# M3H6 register map
File version: 0.1
Registers are 32-bit, read-write, reset 0x0 unless marked. A register's access mark holds for its fields unless they carry their own. Offsets are from the block's base; [hi:lo] are bit positions; {n}, {i} and the like mark numbered series.

## PB — Port B
Base 0x400C0100
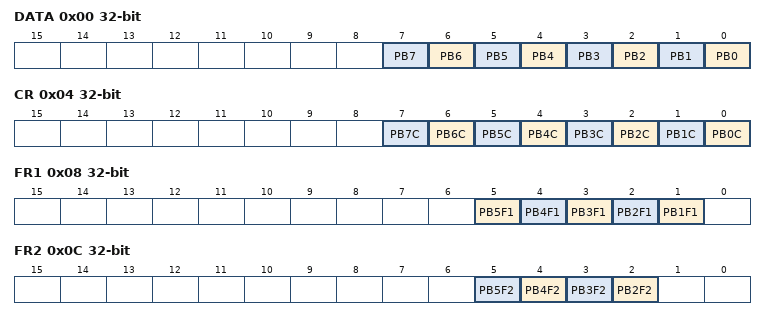
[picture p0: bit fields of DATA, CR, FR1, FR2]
0x00 DATA — PB Data Register
  [n] PB{n} (n=0..7)
0x04 CR — PB Control Register
  [n] PB{n}C (n=0..7)
0x08 FR1 — PB Function Register 1
  [n] PB{n}F1 (n=1..5)
0x0C FR2 — PB Function Register 2
  [n] PB{n}F2 (n=2..5)
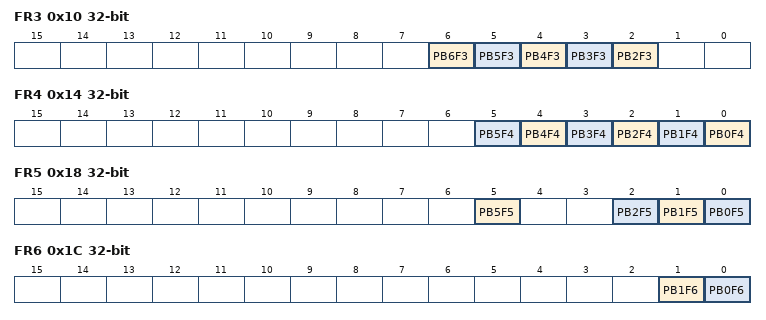
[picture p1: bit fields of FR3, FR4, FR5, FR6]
0x10 FR3 — PB Function Register 3
  [n] PB{n}F3 (n=2..6)
0x14 FR4 — PB Function Register 4
  [n] PB{n}F4 (n=0..5)
0x18 FR5 — PB Function Register 5
  [5] PB5F5, [2] PB2F5, [1] PB1F5, [0] PB0F5
0x1C FR6 — PB Function Register 6
  [1] PB1F6, [0] PB0F6
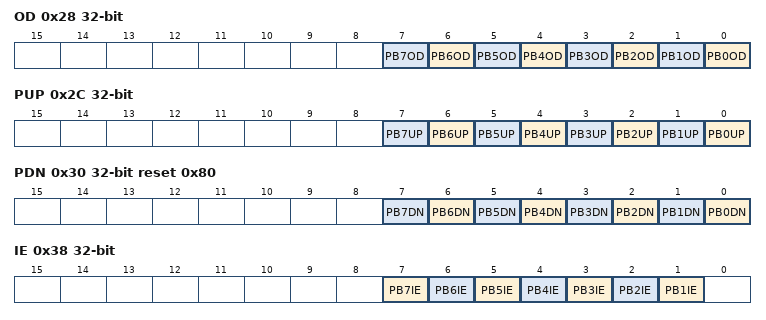
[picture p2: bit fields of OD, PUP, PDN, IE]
0x28 OD — PB Open Drain Control Register
  [n] PB{n}OD (n=0..7)
0x2C PUP — PB Pull-up Control Register
  [n] PB{n}UP (n=0..7)
0x30 PDN reset 0x80 — PB Pull-Down Control Register
  [n] PB{n}DN (n=0..7)
0x38 IE — PB Input Enable Control Register
  [n] PB{n}IE (n=1..7)

## PC — Port C
Base 0x400C0200
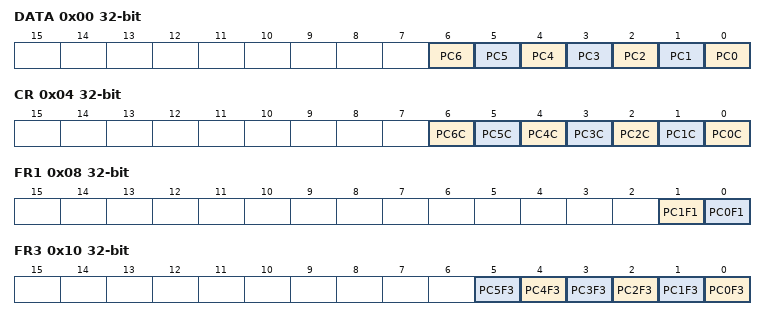
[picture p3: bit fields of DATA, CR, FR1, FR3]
0x00 DATA — PC Data Register
  [n] PC{n} (n=0..6)
0x04 CR — PC Control Register
  [n] PC{n}C (n=0..6)
0x08 FR1 — PC Function Register 1
  [1] PC1F1, [0] PC0F1
0x10 FR3 — PC Function Register 3
  [n] PC{n}F3 (n=0..5)
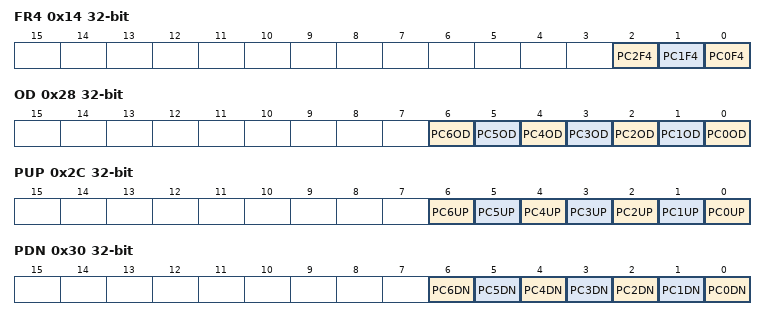
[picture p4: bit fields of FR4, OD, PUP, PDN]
0x14 FR4 — PC Function Register 4
  [2] PC2F4, [1] PC1F4, [0] PC0F4
0x18 FR5 — PC Function Register 5
  [2] PC2F5
0x28 OD — PC Open Drain Control Register
  [n] PC{n}OD (n=0..6)
0x2C PUP — PC Pull-up Control Register
  [n] PC{n}UP (n=0..6)
0x30 PDN — PC Pull-Down Control Register
  [n] PC{n}DN (n=0..6)
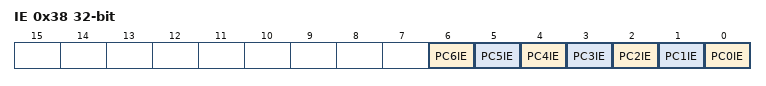
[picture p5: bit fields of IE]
0x38 IE — PC Input Enable Control Register
  [n] PC{n}IE (n=0..6)

## PD — Port D
Base 0x400C0300
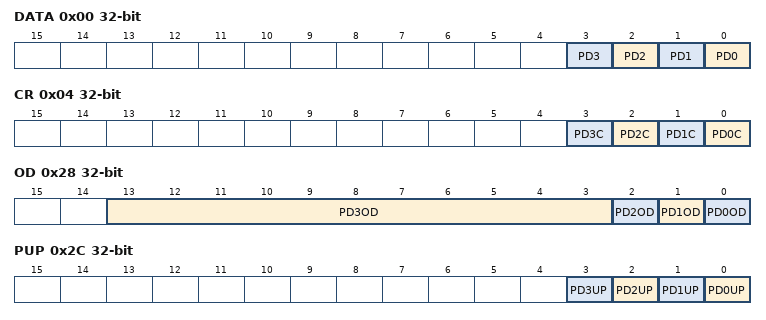
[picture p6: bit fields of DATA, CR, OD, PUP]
0x00 DATA — PD Data Register
  [n] PD{n} (n=0..3)
0x04 CR — PD Control Register
  [n] PD{n}C (n=0..3)
0x28 OD — PD Open Drain Control Register
  [13:3] PD3OD, [2] PD2OD, [1] PD1OD, [0] PD0OD
0x2C PUP — PD Pull-up Control Register
  [n] PD{n}UP (n=0..3)
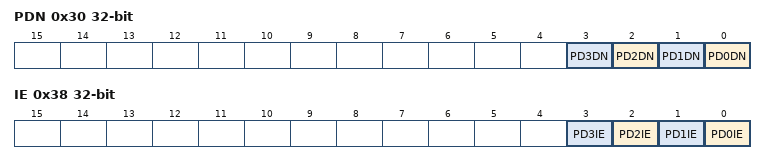
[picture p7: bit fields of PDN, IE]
0x30 PDN — PD Pull-Down Control Register
  [n] PD{n}DN (n=0..3)
0x38 IE — PD Input Enable Control Register
  [n] PD{n}IE (n=0..3)

## PE — Port E
Base 0x400C0400
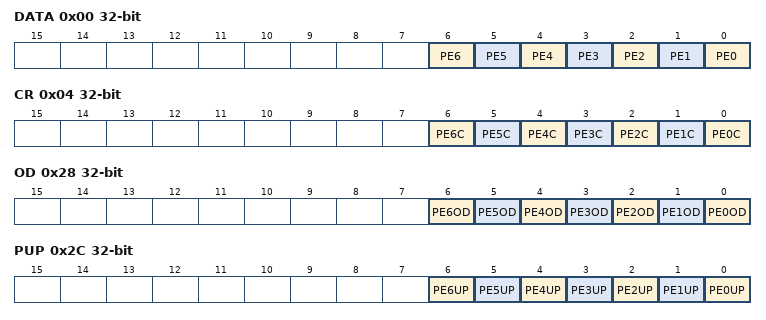
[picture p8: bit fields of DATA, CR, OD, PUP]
0x00 DATA — PE Data Register
  [n] PE{n} (n=0..6)
0x04 CR — PE Control Register
  [n] PE{n}C (n=0..6)
0x28 OD — PE Open Drain Control Register
  [n] PE{n}OD (n=0..6)
0x2C PUP — PE Pull-up Control Register
  [n] PE{n}UP (n=0..6)
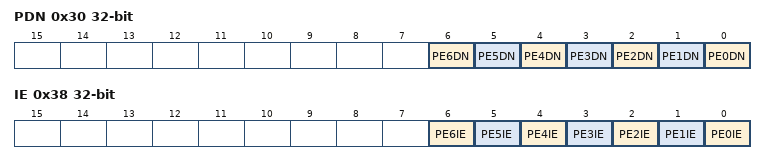
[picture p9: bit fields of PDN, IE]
0x30 PDN — PE Pull-Down Control Register
  [n] PE{n}DN (n=0..6)
0x38 IE — PE Input Enable Control Register
  [n] PE{n}IE (n=0..6)

## PF
Base 0x400C0500
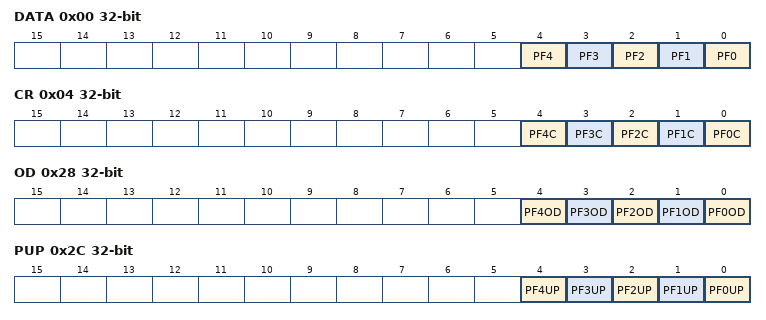
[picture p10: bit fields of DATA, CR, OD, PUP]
0x00 DATA — PF Data Register
  [n] PF{n} (n=0..4)
0x04 CR — PF Control Register
  [n] PF{n}C (n=0..4)
0x28 OD — PF Open Drain Control Register
  [n] PF{n}OD (n=0..4)
0x2C PUP — PF Pull-up Control Register
  [n] PF{n}UP (n=0..4)
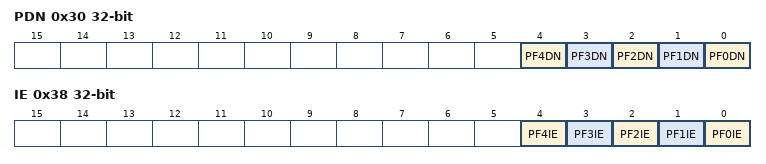
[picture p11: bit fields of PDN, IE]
0x30 PDN — PF Pull-Down Control Register
  [n] PF{n}DN (n=0..4)
0x38 IE — PF Input Enable Control Register
  [n] PF{n}IE (n=0..4)

## PG
Base 0x400C0600
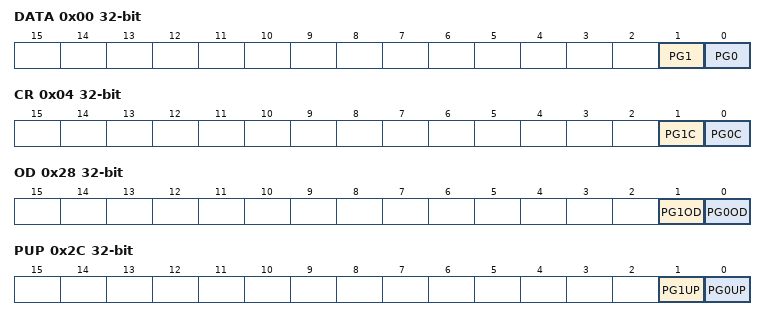
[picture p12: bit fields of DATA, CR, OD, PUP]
0x00 DATA — PG Data Register
  [1] PG1, [0] PG0
0x04 CR — PG Control Register
  [1] PG1C, [0] PG0C
0x28 OD — PG Open Drain Control Register
  [1] PG1OD, [0] PG0OD
0x2C PUP — PG Pull-up Control Register
  [1] PG1UP, [0] PG0UP
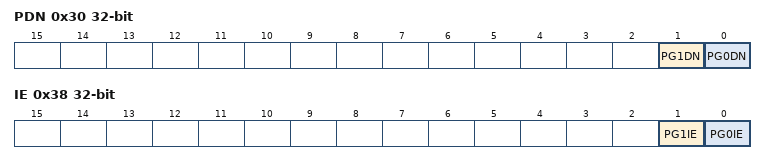
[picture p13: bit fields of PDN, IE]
0x30 PDN — PG Pull-Down Control Register
  [1] PG1DN, [0] PG0DN
0x38 IE — PG Input Enable Control Register
  [1] PG1IE, [0] PG0IE

## PH
Base 0x400C0700
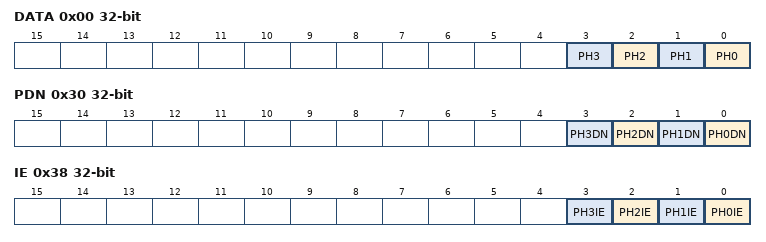
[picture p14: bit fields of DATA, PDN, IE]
0x00 DATA — PH Data Register
  [n] PH{n} (n=0..3)
0x30 PDN — PH Pull-Down Control Register
  [n] PH{n}DN (n=0..3)
0x38 IE — PH Input Enable Control Register
  [n] PH{n}IE (n=0..3)

## PJ
Base 0x400C0800
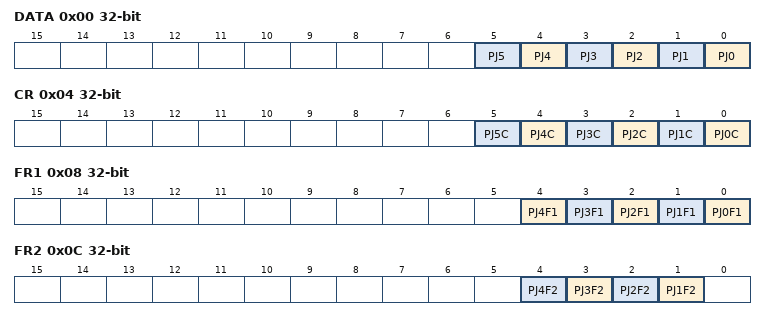
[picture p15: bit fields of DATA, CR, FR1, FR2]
0x00 DATA — PJ Data Register
  [n] PJ{n} (n=0..5)
0x04 CR — PJ Control Register
  [n] PJ{n}C (n=0..5)
0x08 FR1 — PJ Function Register 1
  [n] PJ{n}F1 (n=0..4)
0x0C FR2 — PJ Function Register 2
  [n] PJ{n}F2 (n=1..4)
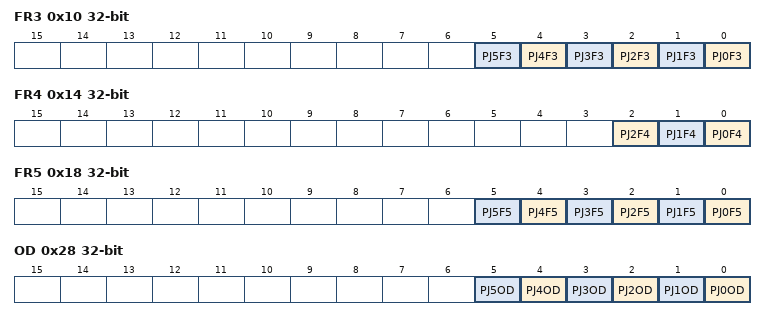
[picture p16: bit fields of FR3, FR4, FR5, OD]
0x10 FR3 — PJ Function Register 3
  [n] PJ{n}F3 (n=0..5)
0x14 FR4 — PJ Function Register 4
  [2] PJ2F4, [1] PJ1F4, [0] PJ0F4
0x18 FR5 — PJ Function Register 5
  [n] PJ{n}F5 (n=0..5)
0x28 OD — PJ Open Drain Control Register
  [n] PJ{n}OD (n=0..5)
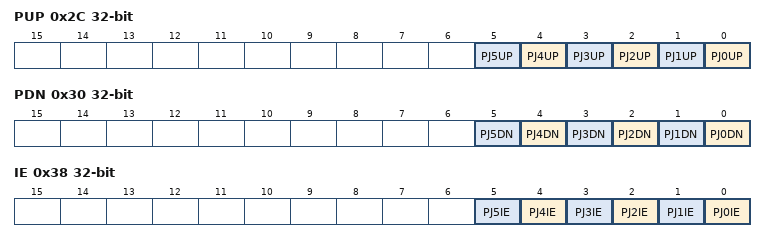
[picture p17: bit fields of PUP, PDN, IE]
0x2C PUP — PJ Pull-up Control Register
  [n] PJ{n}UP (n=0..5)
0x30 PDN — PJ Pull-Down Control Register
  [n] PJ{n}DN (n=0..5)
0x38 IE — PJ Input Enable Control Register
  [n] PJ{n}IE (n=0..5)
